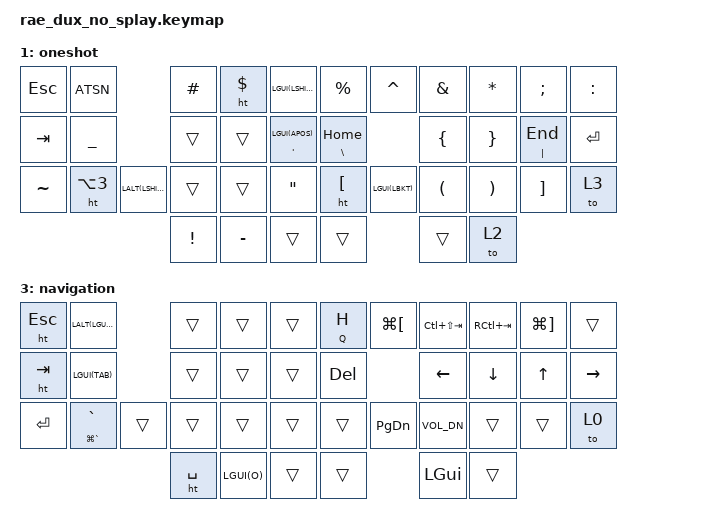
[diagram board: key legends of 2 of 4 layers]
/*
 * Copyright (c) 2021 The ZMK Contributors
 *
 * SPDX-License-Identifier: MIT
 */

#include <behaviors.dtsi>
#include <dt-bindings/zmk/keys.h>
#include <dt-bindings/zmk/bt.h>


&mt {
    flavor = "tap-preferred";
    tapping_term_ms = <200>;
};

&mmv {
   time-to-max-speed-ms = <680>;
   acceleration-exponent=<2>;
};
/   {
        behaviors {
            hm: homerow_mods {
                compatible = "zmk,behavior-hold-tap";
                label = "HOMEROW_MODS";
                #binding-cells = <2>;
                tapping-term-ms = <200>;
                quick_tap_ms = <0>;
                flavor = "tap-preferred";
                bindings = <&kp>, <&kp>;
        };

        td: tapdance {
                compatible = "zmk,behavior-hold-tap";
                label = "TAPDANCE";
                #binding-cells = <2>;
                tapping-term-ms = <150>;
                quick_tap_ms = <0>;
                flavor = "tap-preferred";
                bindings = <&kp>, <&kp>;
        };
    };
    
    keymap {
        compatible = "zmk,keymap";
                
        default_layer {
            bindings = <
                &ht Q LGUI(Q)      &ht W LGUI(W)    &ht E LGUI(E)              &ht R LGUI(R)            &ht T LGUI(T) 			&ht Y LGUI(Y)       &ht U LGUI(U)     &tp I LGUI(I)  &tp O LGUI(O)  &tp P LGUI(P) 
                &ht A LGUI(A)      &ht S LGUI(S)    &ht D LGUI(D)              &tp F LGUI(F)            &ht G LGUI(G)           &ht H LGUI(H)       &ht J LGUI(J)     &ht K LGUI(K)  &ht L LGUI(L)  &ht ö
                &ht Z LGUI(Z)      &ht X LGUI(X)    &ht C LGUI(C)              &ht V LGUI(V)            &ht B LGUI(B)           &ht N LGUI(N)       &ht M LGUI(M)     &ht COMMA LGUI(COMMA)  &ht DOT LGUI(DOT)  &ht SLASH LGUI(SLASH)
                                                    &kp LALT(LSHIFT(LCTRL))    &ht SPACE LGUI(SPACE)    &sk LSHIFT 		        &sk LALT            &sl 1             &sk RCTRL
		    >;
		};

        oneshot {
            bindings = <
                &kp ESC     &kp ATSN                    &kp HASH        &ht DLLR LGUI(LSHIFT(S))    &kp PRCNT		            &kp CARET           &kp AMPS        &kp STAR    &kp SEMI        &kp COLON 
                &kp TAB     &kp UNDER                   &trans          &trans                      &td APOS LGUI(APOS) 	    &ht BSLH HOME       &kp LBRC        &kp RBRC    &ht PIPE END    &kp ENTER
                &kp TILDE   &ht LA(N3) LALT(LSHIFT(2)) 	&trans          &trans                      &kp DQT 	                &ht LBKT LGUI(LBKT) &kp LPRN        &kp RPRN    &kp RBKT        &to 3 
                                                        &kp EXCL        &kp MINUS  				    &trans	                    &trans              &trans          &to 2 
		    >;
		};
		
		num_ctrl {
		    bindings = <
                &kp ESC     &kp C_PP            &kp C_PREV      &kp C_NEXT      &kp UNDER    			    &kp MINUS   &kp N7  &kp N8  &kp N9  &trans
                &kp TAB     &trans              &kp C_VOL_DN    &kp C_VOL_UP    &kp PLUS 			        &kp EQUAL   &kp N4  &kp N5  &kp N6  &kp ENTER
                &trans      &kp KP_MULTIPLY     &trans          &trans          &kp DOT    			        &kp N0      &kp N1  &kp N2  &kp N3  &trans 
                                                &to 0           &sk LGUI        &trans  				    &trans      &trans  &trans 
		    >;
		};
		
		navigation {
		    bindings = <
                &ht ESC LALT(LGUI(ESC))             &trans    &trans  &trans   &ht Q H 			    &kp LG(LBKT)            &kp LC(LS(TAB))     &kp RC(TAB)     &kp LG(RBKT)    &trans
                &ht TAB LGUI(TAB)                   &trans    &trans  &trans   &kp DEL  			&kp LEFT                &kp DOWN            &kp UP          &kp RIGHT       &kp ENTER 
                &td LG(GRAVE) GRAVE                 &trans    &trans  &trans   &trans   		    &trans                  &kp PG_DN           &kp K_VOL_DN    &trans          &trans   
                                                                      &to 0    &ht SPACE LGUI(O)    &trans                  &trans              &kp LGUI        &trans
		    >;
		};      
	};
};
